# Fishball P25 register map
Vendor: Andy Lee; Series: Fishball P25; File version: 0.2.0
Fishball P25 IP core (platform 0)
Registers are 32-bit, read-only, no defined reset value unless marked. A register's access mark holds for its fields unless they carry their own. Offsets are from the block's base; lines under a group give offsets from that group; [hi:lo] are bit positions; {n}, {i} and the like mark numbered series; 'fields as' and 'values as' point back to an identical list; <NAME> marks a mode.

## Memory map
0x00000000 Fishball_P25 size 0x1C8 — Fishball P25 IP core (platform 0)

## Fishball_P25 — Fishball P25 IP core (platform 0)
Base 0x00000000
0x00 product_id
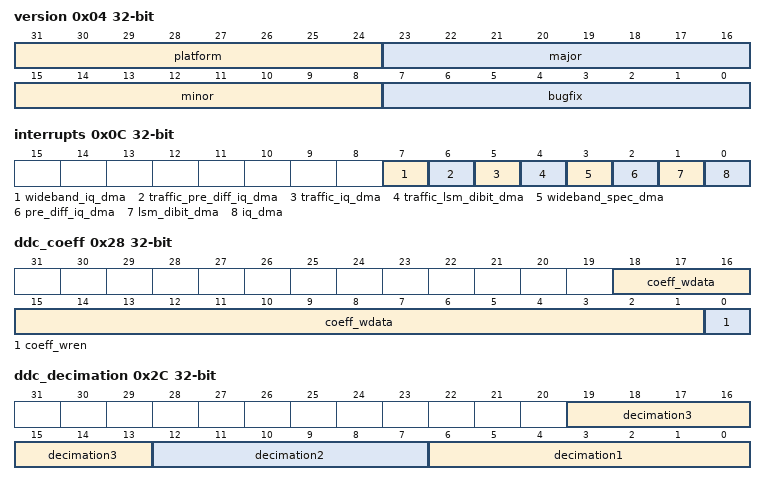
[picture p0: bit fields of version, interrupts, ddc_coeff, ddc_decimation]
0x04 version
  [31:24] platform, [23:16] major, [15:8] minor, [7:0] bugfix
0x08 control rw
  [0] sdr_reset
0x0C interrupts
  [7] wideband_iq_dma, [6] traffic_pre_diff_iq_dma, [5] traffic_iq_dma, [4] traffic_lsm_dibit_dma, [3] wideband_spec_dma, [2] pre_diff_iq_dma, [1] lsm_dibit_dma, [0] iq_dma
0x20 ddc_coeff_addr rw
  [9:0] coeff_waddr
0x28 ddc_coeff rw
  [18:1] coeff_wdata, [0] coeff_wren wo
0x2C ddc_decimation rw
  [19:13] decimation3, [12:7] decimation2, [6:0] decimation1
0x30 ddc_frequency rw
  [27:0] frequency
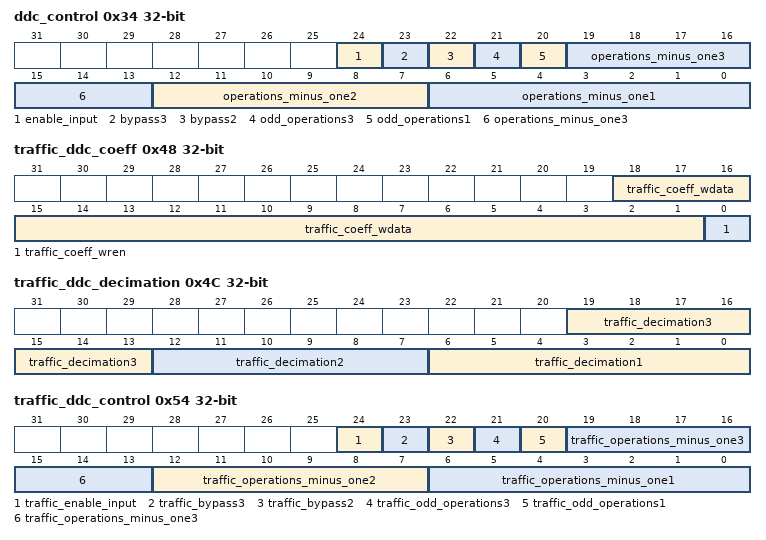
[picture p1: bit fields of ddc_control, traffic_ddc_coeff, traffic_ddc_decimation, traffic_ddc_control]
0x34 ddc_control rw
  [24] enable_input, [23] bypass3, [22] bypass2, [21] odd_operations3, [20] odd_operations1, [19:13] operations_minus_one3, [12:7] operations_minus_one2, [6:0] operations_minus_one1
0x40 traffic_ddc_coeff_addr rw
  [9:0] traffic_coeff_waddr
0x48 traffic_ddc_coeff rw
  [18:1] traffic_coeff_wdata, [0] traffic_coeff_wren wo
0x4C traffic_ddc_decimation rw
  [19:13] traffic_decimation3, [12:7] traffic_decimation2, [6:0] traffic_decimation1
0x50 traffic_ddc_frequency rw
  [27:0] traffic_frequency
0x54 traffic_ddc_control rw
  [24] traffic_enable_input, [23] traffic_bypass3, [22] traffic_bypass2, [21] traffic_odd_operations3, [20] traffic_odd_operations1, [19:13] traffic_operations_minus_one3, [12:7] traffic_operations_minus_one2, [6:0] traffic_operations_minus_one1
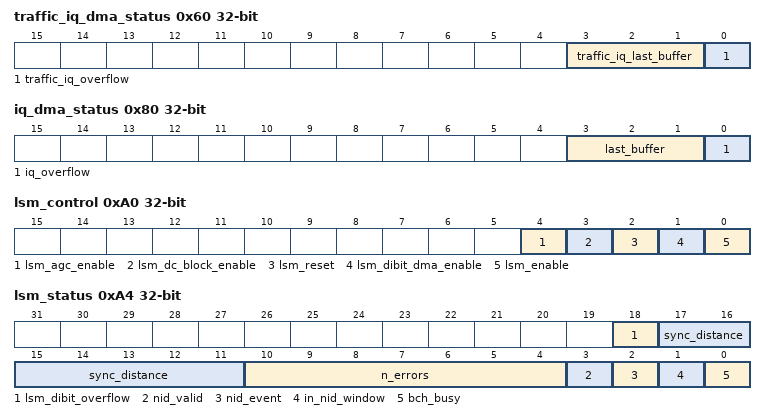
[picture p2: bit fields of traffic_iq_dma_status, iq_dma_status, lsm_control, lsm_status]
0x60 traffic_iq_dma_status
  [3:1] traffic_iq_last_buffer, [0] traffic_iq_overflow
0x64 traffic_iq_dma_control rw
  [0] traffic_iq_enable
0x68 traffic_iq_next_address
  [31:0] next_address
0x80 iq_dma_status
  [3:1] last_buffer, [0] iq_overflow
0x84 iq_dma_control rw
  [0] iq_enable
0x88 iq_next_address
  [31:0] next_address
0xA0 lsm_control rw
  [4] lsm_agc_enable, [3] lsm_dc_block_enable, [2] lsm_reset wo, [1] lsm_dibit_dma_enable, [0] lsm_enable
0xA4 lsm_status
  [18] lsm_dibit_overflow, [17:11] sync_distance, [10:4] n_errors, [3] nid_valid, [2] nid_event, [1] in_nid_window, [0] bch_busy
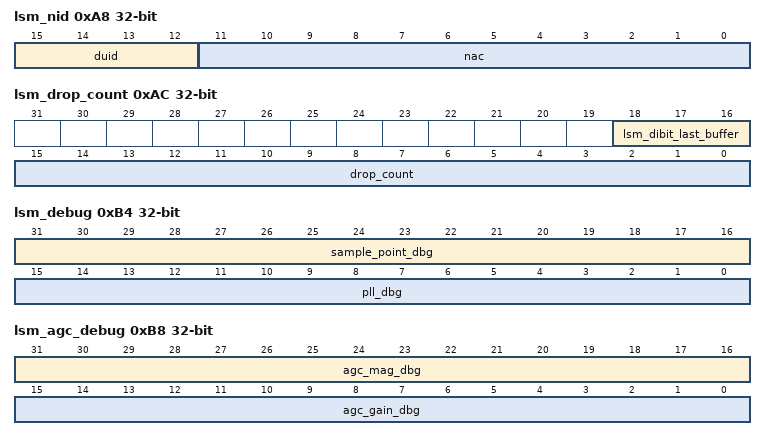
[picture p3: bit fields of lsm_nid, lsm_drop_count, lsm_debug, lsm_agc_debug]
0xA8 lsm_nid
  [15:12] duid, [11:0] nac
0xAC lsm_drop_count
  [18:16] lsm_dibit_last_buffer, [15:0] drop_count
0xB0 lsm_dibit_next
  [31:0] next_address
0xB4 lsm_debug
  [31:16] sample_point_dbg, [15:0] pll_dbg
0xB8 lsm_agc_debug
  [31:16] agc_mag_dbg, [15:0] agc_gain_dbg
0xBC lsm_agc_config rw
  [15:0] mag_update_threshold
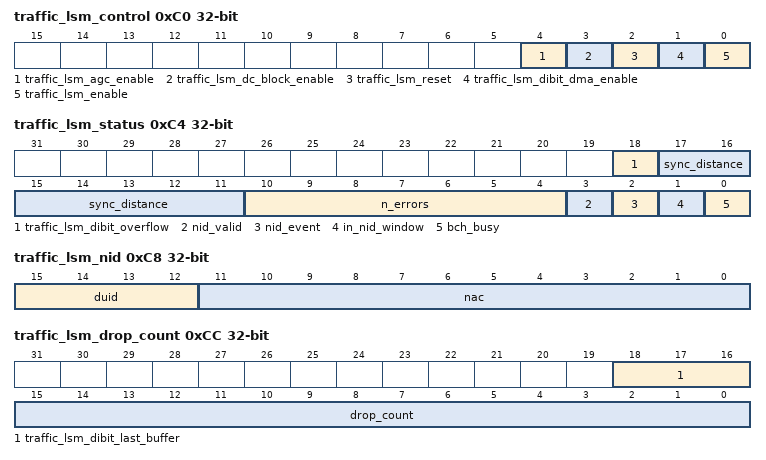
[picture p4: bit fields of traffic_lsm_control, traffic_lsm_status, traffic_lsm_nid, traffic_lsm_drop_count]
0xC0 traffic_lsm_control rw
  [4] traffic_lsm_agc_enable, [3] traffic_lsm_dc_block_enable, [2] traffic_lsm_reset wo, [1] traffic_lsm_dibit_dma_enable, [0] traffic_lsm_enable
0xC4 traffic_lsm_status
  [18] traffic_lsm_dibit_overflow, [17:11] sync_distance, [10:4] n_errors, [3] nid_valid, [2] nid_event, [1] in_nid_window, [0] bch_busy
0xC8 traffic_lsm_nid
  [15:12] duid, [11:0] nac
0xCC traffic_lsm_drop_count
  [18:16] traffic_lsm_dibit_last_buffer, [15:0] drop_count
0xD0 traffic_lsm_dibit_next
  [31:0] next_address
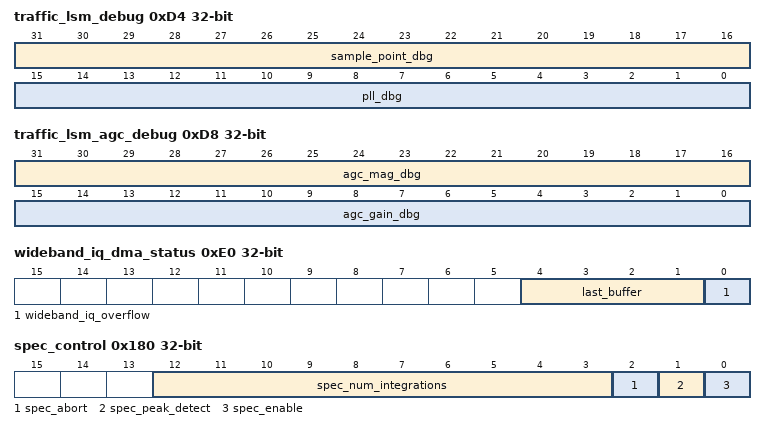
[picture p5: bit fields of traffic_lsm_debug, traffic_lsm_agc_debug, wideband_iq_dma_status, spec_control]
0xD4 traffic_lsm_debug
  [31:16] sample_point_dbg, [15:0] pll_dbg
0xD8 traffic_lsm_agc_debug
  [31:16] agc_mag_dbg, [15:0] agc_gain_dbg
0xDC traffic_lsm_agc_config rw
  [15:0] mag_update_threshold
0xE0 wideband_iq_dma_status
  [4:1] last_buffer, [0] wideband_iq_overflow
0xE4 wideband_iq_dma_control rw
  [0] wideband_iq_enable
0xE8 wideband_iq_next_address
  [31:0] next_address
0x100 lsm_agc_seed rw
  [19:0] agc_seed
0x104 lsm_pll_seed rw
  [15:0] pll_seed
0x108 lsm_timing_seed rw
  [17:0] timing_seed
0x10C traffic_lsm_agc_seed rw
  [19:0] agc_seed
0x110 traffic_lsm_pll_seed rw
  [15:0] pll_seed
0x114 traffic_lsm_timing_seed rw
  [17:0] timing_seed
0x180 spec_control rw
  [12:3] spec_num_integrations, [2] spec_abort wo, [1] spec_peak_detect, [0] spec_enable
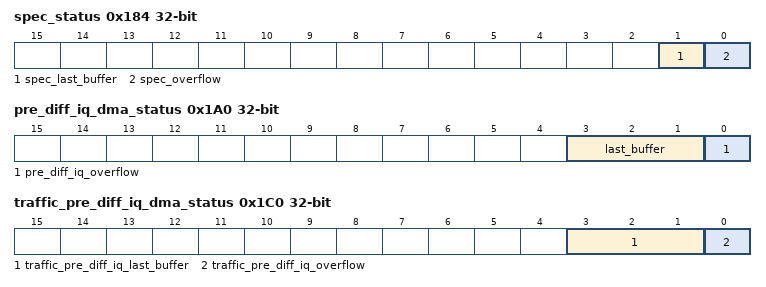
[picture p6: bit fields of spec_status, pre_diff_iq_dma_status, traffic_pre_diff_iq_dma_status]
0x184 spec_status
  [1] spec_last_buffer, [0] spec_overflow
0x188 spec_next_address
  [31:0] next_address
0x1A0 pre_diff_iq_dma_status
  [3:1] last_buffer, [0] pre_diff_iq_overflow
0x1A4 pre_diff_iq_dma_control rw
  [0] pre_diff_iq_enable
0x1A8 pre_diff_iq_next_address
  [31:0] next_address
0x1C0 traffic_pre_diff_iq_dma_status
  [3:1] traffic_pre_diff_iq_last_buffer, [0] traffic_pre_diff_iq_overflow
0x1C4 traffic_pre_diff_iq_dma_control rw
  [0] traffic_pre_diff_iq_enable
0x1C8 traffic_pre_diff_iq_next_address
  [31:0] next_address

## Licence text in the file
SPDX-License-Identifier: MIT
